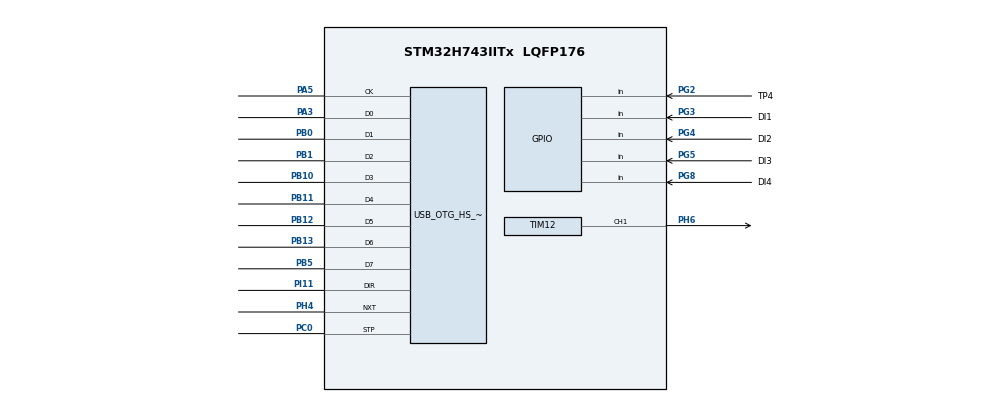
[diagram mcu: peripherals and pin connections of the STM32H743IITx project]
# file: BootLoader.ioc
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Mcu.Family=STM32H7
Mcu.Name=STM32H743IITx
Mcu.Package=LQFP176
NVIC.OTG_HS_IRQn=true\:0\:0\:false\:false\:true\:false\:true
NVIC.PriorityGroup=NVIC_PRIORITYGROUP_4
NVIC.TIM8_TRG_COM_TIM14_IRQn=true\:5\:0\:true\:false\:true\:true\:true
NVIC.TIM8_UP_TIM13_IRQn=true\:10\:0\:true\:false\:true\:true\:true
PA3.Mode=Device_HS
PA3.Signal=USB_OTG_HS_ULPI_D0
PA5.Mode=Device_HS
PA5.Signal=USB_OTG_HS_ULPI_CK
PB0.Mode=Device_HS
PB0.Signal=USB_OTG_HS_ULPI_D1
PB1.Mode=Device_HS
PB1.Signal=USB_OTG_HS_ULPI_D2
PB10.Mode=Device_HS
PB10.Signal=USB_OTG_HS_ULPI_D3
PB11.Mode=Device_HS
PB11.Signal=USB_OTG_HS_ULPI_D4
PB12.Mode=Device_HS
PB12.Signal=USB_OTG_HS_ULPI_D5
PB13.Mode=Device_HS
PB13.Signal=USB_OTG_HS_ULPI_D6
PB5.Mode=Device_HS
PB5.Signal=USB_OTG_HS_ULPI_D7
PC0.Mode=Device_HS
PC0.Signal=USB_OTG_HS_ULPI_STP
PC9.Signal=S_TIM3_CH4
PG2.GPIO_Label=TP4
PG2.GPIO_PuPd=GPIO_PULLDOWN
PG2.Signal=GPIO_Input
PG3.GPIO_Label=DI1
PG3.Signal=GPIO_Input
PG4.GPIO_Label=DI2
PG4.Signal=GPIO_Input
PG5.GPIO_Label=DI3
PG5.Signal=GPIO_Input
PG8.GPIO_Label=DI4
PG8.Signal=GPIO_Input
PH0-OSC_IN\ (PH0).Mode=HSE-External-Clock-Source
PH0-OSC_IN\ (PH0).Signal=RCC_OSC_IN
PH4.Mode=Device_HS
PH4.Signal=USB_OTG_HS_ULPI_NXT
PH6.Signal=S_TIM12_CH1
PI11.Mode=Device_HS
PI11.Signal=USB_OTG_HS_ULPI_DIR
ProjectManager.HeapSize=0x2000
ProjectManager.StackSize=0x4000
ProjectManager.TargetToolchain=MDK-ARM V5
RCC.ADCFreq_Value=100781250
RCC.APB1Freq_Value=120000000
RCC.APB2Freq_Value=120000000
RCC.APB3Freq_Value=120000000
RCC.APB4Freq_Value=120000000
RCC.CortexFreq_Value=480000000
RCC.D1PPRE=RCC_APB3_DIV2
RCC.D2PPRE1=RCC_APB1_DIV2
RCC.D2PPRE2=RCC_APB2_DIV2
RCC.D3PPRE=RCC_APB4_DIV2
RCC.DIVM1=25
RCC.DIVN1=480
RCC.HCLKFreq_Value=240000000
RCC.HPRE=RCC_HCLK_DIV2
RCC.HSE_VALUE=50000000
RCC.PLLSourceVirtual=RCC_PLLSOURCE_HSE
RCC.SYSCLKFreq_VALUE=480000000
RCC.SYSCLKSource=RCC_SYSCLKSOURCE_PLLCLK
RCC.USBFreq_Value=480000000
SH.S_TIM12_CH1.0=TIM12_CH1,PWM Generation1 CH1
SH.S_TIM3_CH4.0=TIM3_CH4
TIM12.AutoReloadPreload=TIM_AUTORELOAD_PRELOAD_ENABLE
TIM12.Channel-PWM\ Generation1\ CH1=TIM_CHANNEL_1
TIM12.OCFastMode_PWM-PWM\ Generation1\ CH1=TIM_OCFAST_ENABLE
TIM12.Period=9
TIM12.Pulse-PWM\ Generation1\ CH1=5
TIM13.AutoReloadPreload=TIM_AUTORELOAD_PRELOAD_ENABLE
TIM13.Period=9999
TIM13.Prescaler=1199
TIM14.AutoReloadPreload=TIM_AUTORELOAD_PRELOAD_ENABLE
TIM14.Period=999
TIM14.Prescaler=119
USB_DEVICE.CLASS_NAME_HS=CDC
USB_DEVICE.MANUFACTURER_STRING-CDC_HS=STMicroelectronics
USB_DEVICE.PRODUCT_STRING_CDC_HS=STM32 Virtual ComPort
USB_DEVICE.VirtualMode-CDC_HS=Cdc
USB_DEVICE.VirtualModeHS=Cdc_HS
USB_OTG_HS.VirtualMode-Device_HS=Device_HS
VP_TIM12_VS_ClockSourceINT.Mode=Internal
VP_TIM13_VS_ClockSourceINT.Mode=Enable_Timer
VP_TIM14_VS_ClockSourceINT.Mode=Enable_Timer
VP_USB_DEVICE_VS_USB_DEVICE_CDC_HS.Mode=CDC_HS
board=custom

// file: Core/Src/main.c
/* USER CODE BEGIN Header */
/**
  ******************************************************************************
  * @file           : main.c
  * @brief          : Main program body
  ******************************************************************************
  * @attention
  *
  * <h2><center>&copy; Copyright (c) 2020 STMicroelectronics.
  * All rights reserved.</center></h2>
  *
  * This software component is licensed by ST under BSD 3-Clause license,
  * the "License"; You may not use this file except in compliance with the
  * License. You may obtain a copy of the License at:
  *                        opensource.org/licenses/BSD-3-Clause
  *
  ******************************************************************************
  */
/* USER CODE END Header */
#include "main.h"
#include "usb_device.h"

/* USER CODE BEGIN Includes */
#include "USBDriver.h"
#include "Upgrade.h"
/* USER CODE END Includes */

TIM_HandleTypeDef htim12;
TIM_HandleTypeDef htim13;
TIM_HandleTypeDef htim14;

void SystemClock_Config(void);
static void MX_GPIO_Init(void);
static void MX_TIM14_Init(void);
static void MX_TIM13_Init(void);
static void MX_TIM12_Init(void);

int main(void)
{
  /* USER CODE BEGIN 1 */
//for (int i = 0; i < 8; i++)
//{
//NVIC->ICER[i]=0;
//NVIC->ICPR[i]=0;
//}
//__set_PRIMASK(0);
	int timer=0;
  /* USER CODE END 1 */

  /* MCU Configuration--------------------------------------------------------*/

  /* Reset of all peripherals, Initializes the Flash interface and the Systick. */
  HAL_Init();

  /* Configure the system clock */
  SystemClock_Config();

  /* USER CODE BEGIN SysInit */
//HAL_RCC_DeInit();
//__set_PRIMASK(0);
  /* USER CODE END SysInit */

  /* Initialize all configured peripherals */
  MX_GPIO_Init();
  MX_USB_DEVICE_Init();
  MX_TIM14_Init();
  MX_TIM13_Init();
  MX_TIM12_Init();
  /* USER CODE BEGIN 2 */

	iniUSBDriver();
	iniFlyApp();
	iniUpgrade();
  /* USER CODE END 2 */

  /* Infinite loop */
  while (1)
  {

    /* USER CODE BEGIN 3 */

		idleUpgradeTask();
		if(timer%10==0)
		{
				sendLiveFrame(timer);
		}
		timer++;
		HAL_Delay(10);
  }
  /* USER CODE END 3 */
}

void SystemClock_Config(void)
{
  RCC_OscInitTypeDef RCC_OscInitStruct = {0};
  RCC_ClkInitTypeDef RCC_ClkInitStruct = {0};

  /** Supply configuration update enable
  */
  HAL_PWREx_ConfigSupply(PWR_LDO_SUPPLY);
  /** Configure the main internal regulator output voltage
  */
  __HAL_PWR_VOLTAGESCALING_CONFIG(PWR_REGULATOR_VOLTAGE_SCALE0);

  while(!__HAL_PWR_GET_FLAG(PWR_FLAG_VOSRDY)) {}
  /** Initializes the RCC Oscillators according to the specified parameters
  * in the RCC_OscInitTypeDef structure.
  */
  RCC_OscInitStruct.OscillatorType = RCC_OSCILLATORTYPE_HSE;
  RCC_OscInitStruct.HSEState = RCC_HSE_BYPASS;
  RCC_OscInitStruct.PLL.PLLState = RCC_PLL_ON;
  RCC_OscInitStruct.PLL.PLLSource = RCC_PLLSOURCE_HSE;
  RCC_OscInitStruct.PLL.PLLM = 25;
  RCC_OscInitStruct.PLL.PLLN = 480;
  RCC_OscInitStruct.PLL.PLLP = 2;
  RCC_OscInitStruct.PLL.PLLQ = 2;
  RCC_OscInitStruct.PLL.PLLR = 2;
  RCC_OscInitStruct.PLL.PLLRGE = RCC_PLL1VCIRANGE_1;
  RCC_OscInitStruct.PLL.PLLVCOSEL = RCC_PLL1VCOWIDE;
  RCC_OscInitStruct.PLL.PLLFRACN = 0;
  if (HAL_RCC_OscConfig(&RCC_OscInitStruct) != HAL_OK)
  {
    Error_Handler();
  }
  /** Initializes the CPU, AHB and APB buses clocks
  */
  RCC_ClkInitStruct.ClockType = RCC_CLOCKTYPE_HCLK|RCC_CLOCKTYPE_SYSCLK
                              |RCC_CLOCKTYPE_PCLK1|RCC_CLOCKTYPE_PCLK2
                              |RCC_CLOCKTYPE_D3PCLK1|RCC_CLOCKTYPE_D1PCLK1;
  RCC_ClkInitStruct.SYSCLKSource = RCC_SYSCLKSOURCE_PLLCLK;
  RCC_ClkInitStruct.SYSCLKDivider = RCC_SYSCLK_DIV1;
  RCC_ClkInitStruct.AHBCLKDivider = RCC_HCLK_DIV2;
  RCC_ClkInitStruct.APB3CLKDivider = RCC_APB3_DIV2;
  RCC_ClkInitStruct.APB1CLKDivider = RCC_APB1_DIV2;
  RCC_ClkInitStruct.APB2CLKDivider = RCC_APB2_DIV2;
  RCC_ClkInitStruct.APB4CLKDivider = RCC_APB4_DIV2;

  if (HAL_RCC_ClockConfig(&RCC_ClkInitStruct, FLASH_LATENCY_4) != HAL_OK)
  {
    Error_Handler();
  }
}

static void MX_TIM12_Init(void)
{

  TIM_ClockConfigTypeDef sClockSourceConfig = {0};
  TIM_OC_InitTypeDef sConfigOC = {0};

  htim12.Instance = TIM12;
  htim12.Init.Prescaler = 0;
  htim12.Init.CounterMode = TIM_COUNTERMODE_UP;
  htim12.Init.Period = 9;
  htim12.Init.ClockDivision = TIM_CLOCKDIVISION_DIV1;
  htim12.Init.AutoReloadPreload = TIM_AUTORELOAD_PRELOAD_ENABLE;
  if (HAL_TIM_Base_Init(&htim12) != HAL_OK)
  {
    Error_Handler();
  }
  sClockSourceConfig.ClockSource = TIM_CLOCKSOURCE_INTERNAL;
  if (HAL_TIM_ConfigClockSource(&htim12, &sClockSourceConfig) != HAL_OK)
  {
    Error_Handler();
  }
  if (HAL_TIM_PWM_Init(&htim12) != HAL_OK)
  {
    Error_Handler();
  }
  sConfigOC.OCMode = TIM_OCMODE_PWM1;
  sConfigOC.Pulse = 5;
  sConfigOC.OCPolarity = TIM_OCPOLARITY_HIGH;
  sConfigOC.OCFastMode = TIM_OCFAST_ENABLE;
  if (HAL_TIM_PWM_ConfigChannel(&htim12, &sConfigOC, TIM_CHANNEL_1) != HAL_OK)
  {
    Error_Handler();
  }
  HAL_TIM_MspPostInit(&htim12);

}

static void MX_TIM13_Init(void)
{

  htim13.Instance = TIM13;
  htim13.Init.Prescaler = 2399;
  htim13.Init.CounterMode = TIM_COUNTERMODE_UP;
  htim13.Init.Period = 9999;
  htim13.Init.ClockDivision = TIM_CLOCKDIVISION_DIV1;
  htim13.Init.AutoReloadPreload = TIM_AUTORELOAD_PRELOAD_ENABLE;
  if (HAL_TIM_Base_Init(&htim13) != HAL_OK)
  {
    Error_Handler();
  }

}

static void MX_TIM14_Init(void)
{

  htim14.Instance = TIM14;
  htim14.Init.Prescaler = 119;
  htim14.Init.CounterMode = TIM_COUNTERMODE_UP;
  htim14.Init.Period = 999;
  htim14.Init.ClockDivision = TIM_CLOCKDIVISION_DIV1;
  htim14.Init.AutoReloadPreload = TIM_AUTORELOAD_PRELOAD_ENABLE;
  if (HAL_TIM_Base_Init(&htim14) != HAL_OK)
  {
    Error_Handler();
  }

}

static void MX_GPIO_Init(void)
{
  GPIO_InitTypeDef GPIO_InitStruct = {0};

  /* GPIO Ports Clock Enable */
  __HAL_RCC_GPIOI_CLK_ENABLE();
  __HAL_RCC_GPIOH_CLK_ENABLE();
  __HAL_RCC_GPIOC_CLK_ENABLE();
  __HAL_RCC_GPIOA_CLK_ENABLE();
  __HAL_RCC_GPIOB_CLK_ENABLE();
  __HAL_RCC_GPIOG_CLK_ENABLE();

  /*Configure GPIO pin : TP4_Pin */
  GPIO_InitStruct.Pin = TP4_Pin;
  GPIO_InitStruct.Mode = GPIO_MODE_INPUT;
  GPIO_InitStruct.Pull = GPIO_PULLDOWN;
  HAL_GPIO_Init(TP4_GPIO_Port, &GPIO_InitStruct);

  /*Configure GPIO pins : DI1_Pin DI2_Pin DI3_Pin DI4_Pin */
  GPIO_InitStruct.Pin = DI1_Pin|DI2_Pin|DI3_Pin|DI4_Pin;
  GPIO_InitStruct.Mode = GPIO_MODE_INPUT;
  GPIO_InitStruct.Pull = GPIO_NOPULL;
  HAL_GPIO_Init(GPIOG, &GPIO_InitStruct);

  /*Configure GPIO pin : PC9 */
  GPIO_InitStruct.Pin = GPIO_PIN_9;
  GPIO_InitStruct.Mode = GPIO_MODE_AF_PP;
  GPIO_InitStruct.Pull = GPIO_NOPULL;
  GPIO_InitStruct.Speed = GPIO_SPEED_FREQ_LOW;
  GPIO_InitStruct.Alternate = GPIO_AF2_TIM3;
  HAL_GPIO_Init(GPIOC, &GPIO_InitStruct);

}

void Error_Handler(void)
{
}

/************************ (C) COPYRIGHT STMicroelectronics *****END OF FILE****/
